# LPC844 register map
Vendor: nxp.com; File version: 1.0
CPU: CM0PLUS r0p0, little endian, no MPU, no FPU, VTOR, 2 interrupt priority bits
Registers are 32-bit, read-write, reset 0x0 unless marked. A register's access mark holds for its fields unless they carry their own. Offsets are from the block's base; [hi:lo] are bit positions; {n}, {i} and the like mark numbered series.

## SWM0 — LPC84x SWM
Base 0x4000C000
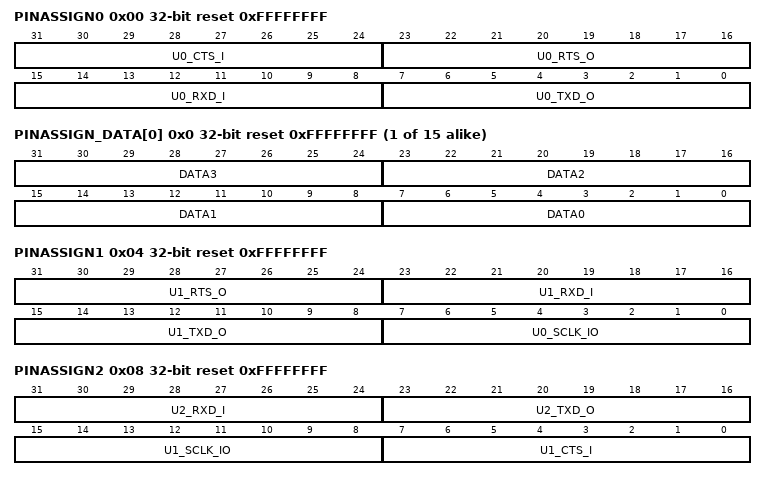
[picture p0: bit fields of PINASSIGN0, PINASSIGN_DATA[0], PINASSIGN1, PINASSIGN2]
0x00 PINASSIGN0 reset 0xFFFFFFFF (PINASSIGN_PINASSIGN_DATA view) — Pin assign register 0. Assign movable functions U0_TXD, U0_RXD, U0_RTS, U0_CTS.
  [31:24] U0_CTS_I — U0_CTS function assignment. The value is the pin number to be assigned to this function. The following pins are available: PIO0_0 (= 0) to PIO0_31 (= 0x1F) and from PIO1_0 (=0x20) to PIO1_21(=0x35).
  [23:16] U0_RTS_O — U0_RTS function assignment. The value is the pin number to be assigned to this function. The following pins are available: PIO0_0 (= 0) to PIO0_31 (= 0x1F) and from PIO1_0 (=0x20) to PIO1_21(=0x35).
  [15:8] U0_RXD_I — U0_RXD function assignment. The value is the pin number to be assigned to this function. The following pins are available: PIO0_0 (= 0) to PIO0_31 (= 0x1F) and from PIO1_0 (=0x20) to PIO1_21(=0x35).
  [7:0] U0_TXD_O — U0_TXD function assignment. The value is the pin number to be assigned to this function. The following pins are available: PIO0_0 (= 0) to PIO0_31 (= 0x1F) and from PIO1_0 (=0x20) to PIO1_21(=0x35) .
{0x0+4i} PINASSIGN_DATA[{i}] (i=0..14) reset 0xFFFFFFFF (PINASSIGN_PINASSIGN_DATA view) — Pin assign register
  [31:24] DATA3 — T0_CAP2 function assignment. The value is the pin number to be assigned to this function. The following pins are available: PIO0_0 (= 0) to PIO0_31 (= 0x1F) and from PIO1_0 (=0x20) to PIO1_21(=0x35).
  [23:16] DATA2 — T0_CAP1 function assignment. The value is the pin number to be assigned to this function. The following pins are available: PIO0_0 (= 0) to PIO0_31 (= 0x1F) and from PIO1_0 (=0x20) to PIO1_21(=0x35).
  [15:8] DATA1 — T0_CAP0 function assignment. The value is the pin number to be assigned to this function. The following pins are available: PIO0_0 (= 0) to PIO0_31 (= 0x1F) and from PIO1_0 (=0x20) to PIO1_21(=0x35).
  [7:0] DATA0 — T0_MAT3 function assignment. The value is the pin number to be assigned to this function. The following pins are available: PIO0_0 (= 0) to PIO0_31 (= 0x1F) and from PIO1_0 (=0x20) to PIO1_21(=0x35).
0x04 PINASSIGN1 reset 0xFFFFFFFF (PINASSIGN_PINASSIGN_DATA view) — Pin assign register 1. Assign movable functions U0_SCLK, U1_TXD, U1_RXD, U1_RTS.
  [31:24] U1_RTS_O — U1_RTS function assignment. The value is the pin number to be assigned to this function. The following pins are available: PIO0_0 (= 0) to PIO0_31 (= 0x1F) and from PIO1_0 (=0x20) to PIO1_21(=0x35).
  [23:16] U1_RXD_I — U1_RXD function assignment. The value is the pin number to be assigned to this function. The following pins are available: PIO0_0 (= 0) to PIO0_31 (= 0x1F) and from PIO1_0 (=0x20) to PIO1_21(=0x35).
  [15:8] U1_TXD_O — U1_TXD function assignment. The value is the pin number to be assigned to this function. The following pins are available: PIO0_0 (= 0) to PIO0_31 (= 0x1F) and from PIO1_0 (=0x20) to PIO1_21(=0x35).
  [7:0] U0_SCLK_IO — U0_SCLK function assignment. The value is the pin number to be assigned to this function. The following pins are available: PIO0_0 (= 0) to PIO0_31 (= 0x1F) and from PIO1_0 (=0x20) to PIO1_21(=0x35).
0x08 PINASSIGN2 reset 0xFFFFFFFF (PINASSIGN_PINASSIGN_DATA view) — Pin assign register 2. Assign movable functions U1_CTS, U1_SCLK, U2_TXD, U2_RXD.
  [31:24] U2_RXD_I — U2_RXD function assignment. The value is the pin number to be assigned to this function. The following pins are available: PIO0_0 (= 0) to PIO0_31 (= 0x1F) and from PIO1_0 (=0x20) to PIO1_21(=0x35).
  [23:16] U2_TXD_O — U2_TXD function assignment. The value is the pin number to be assigned to this function. The following pins are available: PIO0_0 (= 0) to PIO0_31 (= 0x1F) and from PIO1_0 (=0x20) to PIO1_21(=0x35).
  [15:8] U1_SCLK_IO — U1_SCLK function assignment. The value is the pin number to be assigned to this function. The following pins are available: PIO0_0 (= 0) to PIO0_31 (= 0x1F) and from PIO1_0 (=0x20) to PIO1_21(=0x35).
  [7:0] U1_CTS_I — U1_CTS function assignment. The value is the pin number to be assigned to this function. The following pins are available: PIO0_0 (= 0) to PIO0_31 (= 0x1F) and from PIO1_0 (=0x20) to PIO1_21(=0x35).
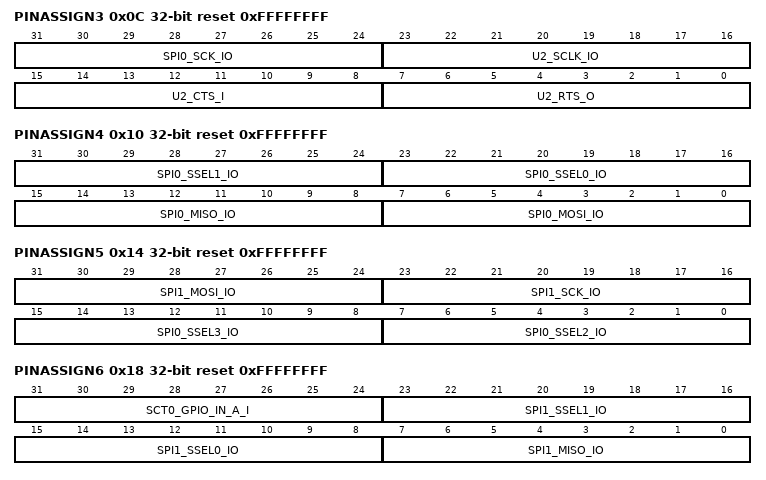
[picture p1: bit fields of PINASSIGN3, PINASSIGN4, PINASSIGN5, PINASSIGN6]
0x0C PINASSIGN3 reset 0xFFFFFFFF (PINASSIGN_PINASSIGN_DATA view) — Pin assign register 3. Assign movable function U2_RTS, U2_CTS, U2_SCLK, SPI0_SCK.
  [31:24] SPI0_SCK_IO — SPI0_SCK function assignment. The value is the pin number to be assigned to this function. The following pins are available: PIO0_0 (= 0) to PIO0_31 (= 0x1F) and from PIO1_0 (=0x20) to PIO1_21(=0x35).
  [23:16] U2_SCLK_IO — U2_SCLK function assignment. The value is the pin number to be assigned to this function. The following pins are available: PIO0_0 (= 0) to PIO0_31 (= 0x1F) and from PIO1_0 (=0x20) to PIO1_21(=0x35).
  [15:8] U2_CTS_I — U2_CTS function assignment. The value is the pin number to be assigned to this function. The following pins are available: PIO0_0 (= 0) to PIO0_31 (= 0x1F) and from PIO1_0 (=0x20) to PIO1_21(=0x35).
  [7:0] U2_RTS_O — U2_RTS function assignment. The value is the pin number to be assigned to this function. The following pins are available: PIO0_0 (= 0) to PIO0_31 (= 0x1F) and from PIO1_0 (=0x20) to PIO1_21(=0x35).
0x10 PINASSIGN4 reset 0xFFFFFFFF (PINASSIGN_PINASSIGN_DATA view) — Pin assign register 4. Assign movable functions SPI0_MOSI, SPI0_MISO, SPI0_SSEL0, SPI0_SSEL1.
  [31:24] SPI0_SSEL1_IO — SPI0_SSEL1 function assignment. The value is the pin number to be assigned to this function. The following pins are available: PIO0_0 (= 0) to PIO0_31 (= 0x1F) and from PIO1_0 (=0x20) to PIO1_21(=0x35).
  [23:16] SPI0_SSEL0_IO — SPI0_SSEL0 function assignment. The value is the pin number to be assigned to this function. The following pins are available: PIO0_0 (= 0) to PIO0_31 (= 0x1F) and from PIO1_0 (=0x20) to PIO1_21(=0x35).
  [15:8] SPI0_MISO_IO — SPI0_MISIO function assignment. The value is the pin number to be assigned to this function. The following pins are available: PIO0_0 (= 0) to PIO0_31 (= 0x1F) and from PIO1_0 (=0x20) to PIO1_21(=0x35).
  [7:0] SPI0_MOSI_IO — SPI0_MOSI function assignment. The value is the pin number to be assigned to this function. The following pins are available: PIO0_0 (= 0) to PIO0_31 (= 0x1F) and from PIO1_0 (=0x20) to PIO1_21(=0x35).
0x14 PINASSIGN5 reset 0xFFFFFFFF (PINASSIGN_PINASSIGN_DATA view) — Pin assign register 5. Assign movable functions SPI0_SSEL2, SPI0_SSEL3, SPI1_SCK, SPI1_MOSI
  [31:24] SPI1_MOSI_IO — SPI1_MOSI function assignment. The value is the pin number to be assigned to this function. The following pins are available: PIO0_0 (= 0) to PIO0_31 (= 0x1F) and from PIO1_0 (=0x20) to PIO1_21(=0x35).
  [23:16] SPI1_SCK_IO — SPI1_SCK function assignment. The value is the pin number to be assigned to this function. The following pins are available: PIO0_0 (= 0) to PIO0_31 (= 0x1F) and from PIO1_0 (=0x20) to PIO1_21(=0x35).
  [15:8] SPI0_SSEL3_IO — SPI0_SSEL3 function assignment. The value is the pin number to be assigned to this function. The following pins are available: PIO0_0 (= 0) to PIO0_31 (= 0x1F) and from PIO1_0 (=0x20) to PIO1_21(=0x35).
  [7:0] SPI0_SSEL2_IO — SPI0_SSEL2 function assignment. The value is the pin number to be assigned to this function. The following pins are available: PIO0_0 (= 0) to PIO0_31 (= 0x1F) and from PIO1_0 (=0x20) to PIO1_21(=0x35).
0x18 PINASSIGN6 reset 0xFFFFFFFF (PINASSIGN_PINASSIGN_DATA view) — Pin assign register 6. Assign movable functions SPI1_MISO, SPI1_SSEL0, SPI1_SSEL1, SCT0_IN0.
  [31:24] SCT0_GPIO_IN_A_I — SCT0_GPIO_IN_A function assignment. The value is the pin number to be assigned to this function. The following pins are available: PIO0_0 (= 0) to PIO0_31 (= 0x1F) and from PIO1_0 (=0x20) to PIO1_21(=0x35).
  [23:16] SPI1_SSEL1_IO — SPI1_SSEL1 function assignment. The value is the pin number to be assigned to this function. The following pins are available: PIO0_0 (= 0) to PIO0_31 (= 0x1F) and from PIO1_0 (=0x20) to PIO1_21(=0x35).
  [15:8] SPI1_SSEL0_IO — SPI1_SSEL0 function assignment. The value is the pin number to be assigned to this function. The following pins are available: PIO0_0 (= 0) to PIO0_31 (= 0x1F) and from PIO1_0 (=0x20) to PIO1_21(=0x35).
  [7:0] SPI1_MISO_IO — SPI1_MISO function assignment. The value is the pin number to be assigned to this function. The following pins are available: PIO0_0 (= 0) to PIO0_31 (= 0x1F) and from PIO1_0 (=0x20) to PIO1_21(=0x35).
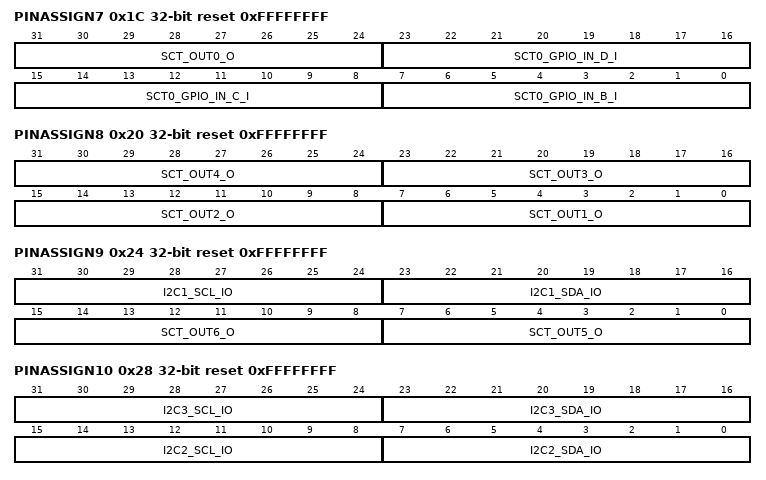
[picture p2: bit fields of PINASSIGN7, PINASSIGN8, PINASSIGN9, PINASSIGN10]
0x1C PINASSIGN7 reset 0xFFFFFFFF (PINASSIGN_PINASSIGN_DATA view) — Pin assign register 7. Assign movable functions SCT_IN1, SCT_IN2, SCT_IN3, SCT_OUT0.
  [31:24] SCT_OUT0_O — SCT_OUT0 function assignment. The value is the pin number to be assigned to this function. The following pins are available: PIO0_0 (= 0) to PIO0_31 (= 0x1F) and from PIO1_0 (=0x20) to PIO1_21(=0x35).
  [23:16] SCT0_GPIO_IN_D_I — SCT0_GPIO_IN_D function assignment. The value is the pin number to be assigned to this function. The following pins are available: PIO0_0 (= 0) to PIO0_31 (= 0x1F) and from PIO1_0 (=0x20) to PIO1_21(=0x35).
  [15:8] SCT0_GPIO_IN_C_I — SCT0_GPIO_IN_C function assignment. The value is the pin number to be assigned to this function. The following pins are available: PIO0_0 (= 0) to PIO0_31 (= 0x1F) and from PIO1_0 (=0x20) to PIO1_21(=0x35).
  [7:0] SCT0_GPIO_IN_B_I — SCT0_GPIO_IN_B function assignment. The value is the pin number to be assigned to this function. The following pins are available: PIO0_0 (= 0) to PIO0_31 (= 0x1F) and from PIO1_0 (=0x20) to PIO1_21(=0x35).
0x20 PINASSIGN8 reset 0xFFFFFFFF (PINASSIGN_PINASSIGN_DATA view) — Pin assign register 8. Assign movable functions SCT_OUT1, SCT_OUT2, SCT_OUT3, SCT_OUT4.
  [8n-1:8n-8] SCT_OUT{n}_O (n=1..4) — SCT_OUT{n} function assignment. The value is the pin number to be assigned to this function. The following pins are available: PIO0_0 (= 0) to PIO0_31 (= 0x1F) and from PIO1_0 (=0x20) to PIO1_21(=0x35).
0x24 PINASSIGN9 reset 0xFFFFFFFF (PINASSIGN_PINASSIGN_DATA view) — Pin assign register 9. Assign movable functions SCT_OUT5, SCT_OUT6, I2C1_SDA, I2C1_SCL.
  [31:24] I2C1_SCL_IO — I2C1_SCL function assignment. The value is the pin number to be assigned to this function. The following pins are available: PIO0_0 (= 0) to PIO0_31 (= 0x1F) and from PIO1_0 (=0x20) to PIO1_21(=0x35).
  [23:16] I2C1_SDA_IO — I2C1_SDA function assignment. The value is the pin number to be assigned to this function. The following pins are available: PIO0_0 (= 0) to PIO0_31 (= 0x1F) and from PIO1_0 (=0x20) to PIO1_21(=0x35).
  [15:8] SCT_OUT6_O — SCT_OUT6 function assignment. The value is the pin number to be assigned to this function. The following pins are available: PIO0_0 (= 0) to PIO0_31 (= 0x1F) and from PIO1_0 (=0x20) to PIO1_21(=0x35).
  [7:0] SCT_OUT5_O — SCT_OUT5 function assignment. The value is the pin number to be assigned to this function. The following pins are available: PIO0_0 (= 0) to PIO0_31 (= 0x1F) and from PIO1_0 (=0x20) to PIO1_21(=0x35).
0x28 PINASSIGN10 reset 0xFFFFFFFF (PINASSIGN_PINASSIGN_DATA view) — Pin assign register 10. Assign movable functions I2C2_SDA, I2C2_SCL, I2C3_SDA, I2C3_SCL, ADC_PINTRIG0.
  [31:24] I2C3_SCL_IO — I2C3_SCL function assignment. The value is the pin number to be assigned to this function. The following pins are available: PIO0_0 (= 0) to PIO0_31 (= 0x1F) and from PIO1_0 (=0x20) to PIO1_21(=0x35).
  [23:16] I2C3_SDA_IO — I2C3_SDA function assignment. The value is the pin number to be assigned to this function. The following pins are available: PIO0_0 (= 0) to PIO0_31 (= 0x1F) and from PIO1_0 (=0x20) to PIO1_21(=0x35).
  [15:8] I2C2_SCL_IO — I2C1_SCL function assignment. The value is the pin number to be assigned to this function. The following pins are available: PIO0_0 (= 0) to PIO0_31 (= 0x1F) and from PIO1_0 (=0x20) to PIO1_21(=0x35).
  [7:0] I2C2_SDA_IO — I2C1_SDA function assignment. The value is the pin number to be assigned to this function. The following pins are available: PIO0_0 (= 0) to PIO0_31 (= 0x1F) and from PIO1_0 (=0x20) to PIO1_21(=0x35).
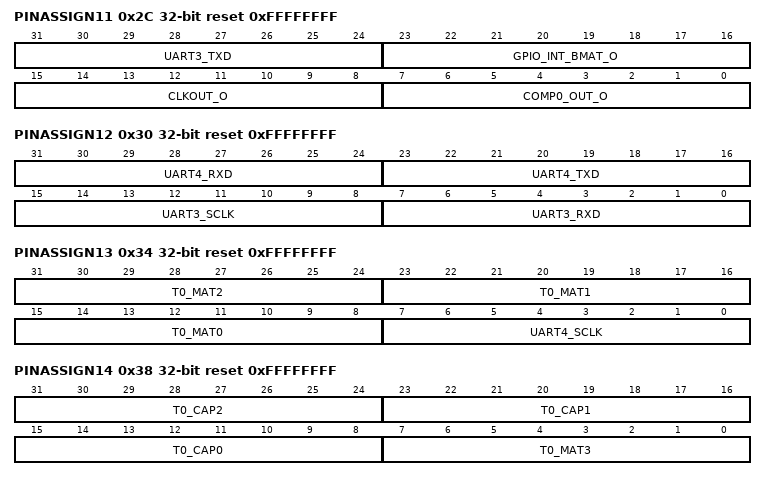
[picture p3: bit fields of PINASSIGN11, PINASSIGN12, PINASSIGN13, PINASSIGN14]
0x2C PINASSIGN11 reset 0xFFFFFFFF (PINASSIGN_PINASSIGN_DATA view) — Pin assign register 11. Assign movable functions COMP0_OUT, CLKOUT, GPIOINT_BMATCH, UART3_TXD
  [31:24] UART3_TXD — UART3_TXD function assignment. The value is the pin number to be assigned to this function. The following pins are available: PIO0_0 (= 0) to PIO0_31 (= 0x1F) and from PIO1_0 (=0x20) to PIO1_21(=0x35).
  [23:16] GPIO_INT_BMAT_O — GPIO_INT_BMAT function assignment. The value is the pin number to be assigned to this function. The following pins are available: PIO0_0 (= 0) to PIO0_31 (= 0x1F) and from PIO1_0 (=0x20) to PIO1_21(=0x35).
  [15:8] CLKOUT_O — CLKOUT function assignment. The value is the pin number to be assigned to this function. The following pins are available: PIO0_0 (= 0) to PIO0_31 (= 0x1F) and from PIO1_0 (=0x20) to PIO1_21(=0x35).
  [7:0] COMP0_OUT_O — COMP0_OUT function assignment. The value is the pin number to be assigned to this function. The following pins are available: PIO0_0 (= 0) to PIO0_31 (= 0x1F) and from PIO1_0 (=0x20) to PIO1_21(=0x35).
0x30 PINASSIGN12 reset 0xFFFFFFFF (PINASSIGN_PINASSIGN_DATA view) — Pin assign register 12. Assign movable functions UART3_RXD, UART3_SCLK, UART4_TXD, UART4_RXD.
  [31:24] UART4_RXD — UART4_TXD function assignment. The value is the pin number to be assigned to this function. The following pins are available: PIO0_0 (= 0) to PIO0_31 (= 0x1F) and from PIO1_0 (=0x20) to PIO1_21(=0x35).
  [23:16] UART4_TXD — UART4_TXD function assignment. The value is the pin number to be assigned to this function. The following pins are available: PIO0_0 (= 0) to PIO0_31 (= 0x1F) and from PIO1_0 (=0x20) to PIO1_21(=0x35).
  [15:8] UART3_SCLK — UART3_SCLK function assignment. The value is the pin number to be assigned to this function. The following pins are available: PIO0_0 (= 0) to PIO0_31 (= 0x1F) and from PIO1_0 (=0x20) to PIO1_21(=0x35).
  [7:0] UART3_RXD — UART3_RXD function assignment. The value is the pin number to be assigned to this function. The following pins are available: PIO0_0 (= 0) to PIO0_31 (= 0x1F) and from PIO1_0 (=0x20) to PIO1_21(=0x35).
0x34 PINASSIGN13 reset 0xFFFFFFFF (PINASSIGN_PINASSIGN_DATA view) — Pin assign register 13. Assign movable functions UART4_SCLK, T0_MAT0, T0_MAT1, T0_MAT2.
  [31:24] T0_MAT2 — T0_MAT2 function assignment. The value is the pin number to be assigned to this function. The following pins are available: PIO0_0 (= 0) to PIO0_31 (= 0x1F) and from PIO1_0 (=0x20) to PIO1_21(=0x35).
  [23:16] T0_MAT1 — T0_MAT1 function assignment. The value is the pin number to be assigned to this function. The following pins are available: PIO0_0 (= 0) to PIO0_31 (= 0x1F) and from PIO1_0 (=0x20) to PIO1_21(=0x35).
  [15:8] T0_MAT0 — T0_MAT0 function assignment. The value is the pin number to be assigned to this function. The following pins are available: PIO0_0 (= 0) to PIO0_31 (= 0x1F) and from PIO1_0 (=0x20) to PIO1_21(=0x35).
  [7:0] UART4_SCLK — UART4_SCLK function assignment. The value is the pin number to be assigned to this function. The following pins are available: PIO0_0 (= 0) to PIO0_31 (= 0x1F) and from PIO1_0 (=0x20) to PIO1_21(=0x35).
0x38 PINASSIGN14 reset 0xFFFFFFFF (PINASSIGN_PINASSIGN_DATA view) — Pin assign register 14. Assign movable functions T0_MAT3, T0_CAP0, T0_CAP1, T0_CAP2.
  [31:24] T0_CAP2 — T0_CAP2 function assignment. The value is the pin number to be assigned to this function. The following pins are available: PIO0_0 (= 0) to PIO0_31 (= 0x1F) and from PIO1_0 (=0x20) to PIO1_21(=0x35).
  [23:16] T0_CAP1 — T0_CAP1 function assignment. The value is the pin number to be assigned to this function. The following pins are available: PIO0_0 (= 0) to PIO0_31 (= 0x1F) and from PIO1_0 (=0x20) to PIO1_21(=0x35).
  [15:8] T0_CAP0 — T0_CAP0 function assignment. The value is the pin number to be assigned to this function. The following pins are available: PIO0_0 (= 0) to PIO0_31 (= 0x1F) and from PIO1_0 (=0x20) to PIO1_21(=0x35).
  [7:0] T0_MAT3 — T0_MAT3 function assignment. The value is the pin number to be assigned to this function. The following pins are available: PIO0_0 (= 0) to PIO0_31 (= 0x1F) and from PIO1_0 (=0x20) to PIO1_21(=0x35).
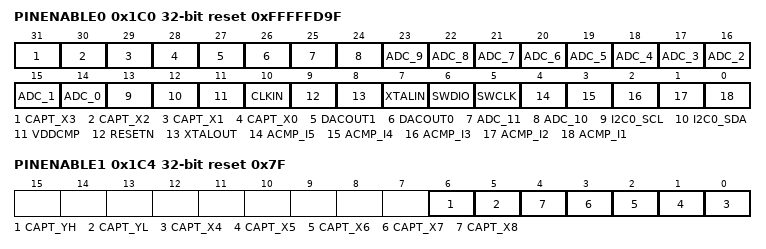
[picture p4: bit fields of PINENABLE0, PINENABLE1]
0x1C0 PINENABLE0 reset 0xFFFFFD9F — Pin enable register 0. Enables fixed-pin functions ACMP_I0, ACMP_I1, SWCLK, SWDIO, XTALIN, XTALOUT, RESET, CLKIN, VDDCMP and so on.
  [31] CAPT_X3 — CAPT_X3 function select.
    0=ENABLED (CAPT_X3 enabled on pin PIO1_2.); 1=DISABLED (CAPT_X3 disabled.)
  [30] CAPT_X2 — CAPT_X2 function select.
    0=ENABLED (CAPT_X2 enabled on pin PIO1_1.); 1=DISABLED (CAPT_X2 disabled.)
  [29] CAPT_X1 — CAPT_X1 function select.
    0=ENABLED (CAPT_X1 enabled on pin PIO1_0.); 1=DISABLED (CAPT_X1 disabled.)
  [28] CAPT_X0 — CAPT_X0 function select.
    0=ENABLED (CAPT_X0 enabled on pin PIO0_31.); 1=DISABLED (CAPT_X0 disabled.)
  [27] DACOUT1 — DACOUT1 function select.
    0=ENABLED (DACOUT1 enabled on pin PIO0_29.); 1=DISABLED (DACOUT1 disabled.)
  [26] DACOUT0 — DACOUT0 function select.
    0=ENABLED (DACOUT0 enabled on pin PIO0_17.); 1=DISABLED (DACOUT0 disabled.)
  [25] ADC_11 — ADC_11 function select.
    0=ENABLED (ADC_11 enabled on pin PIO0_4.); 1=DISABLED (ADC_11 disabled.)
  [24] ADC_10 — ADC_10 function select.
    0=ENABLED (ADC_10 enabled on pin PIO0_13.); 1=DISABLED (ADC_10 disabled.)
  [23] ADC_9 — ADC_9 function select.
    0=ENABLED (ADC_9 enabled on pin PIO0_17.); 1=DISABLED (ADC_9 disabled.)
  [22] ADC_8 — ADC_8 function select.
    0=ENABLED (ADC_8 enabled on pin PIO0_18.); 1=DISABLED (ADC_8 disabled.)
  [21] ADC_7 — ADC_7 function select.
    0=ENABLED (ADC_7 enabled on pin PIO0_19.); 1=DISABLED (ADC_7 disabled.)
  [20] ADC_6 — ADC_6 function select.
    0=ENABLED (ADC_6 enabled on pin PIO0_20.); 1=DISABLED (ADC_6 disabled.)
  [19] ADC_5 — ADC_5 function select.
    0=ENABLED (ADC_5 enabled on pin PIO0_21.); 1=DISABLED (ADC_5 disabled.)
  [18] ADC_4 — ADC_4 function select.
    0=ENABLED (ADC_4 enabled on pin PIO0_22.); 1=DISABLED (ADC_4 disabled.)
  [17] ADC_3 — ADC_3 function select.
    0=ENABLED (ADC_3 enabled on pin PIO0_23.); 1=DISABLED (ADC_3 disabled.)
  [16] ADC_2 — ADC_2 function select.
    0=ENABLED (ADC_2 enabled on pin PIO0_14.); 1=DISABLED (ADC_2 disabled.)
  [15] ADC_1 — ADC_1 function select.
    0=ENABLED (ADC_1 enabled on pin PIO0_6.); 1=DISABLED (ADC_1 disabled.)
  [14] ADC_0 — ADC_0 function select.
    0=ENABLED (ADC_0 enabled on pin PIO0_7.); 1=DISABLED (ADC_0 disabled.)
  [13] I2C0_SCL — I2C0_SCL function select.
    0=ENABLED (I2C0_SCL enabled on pin PIO0_10.); 1=DISABLED (I2C0_SCL disabled.)
  [12] I2C0_SDA — I2C0_SDA function select.
    0=ENABLED (I2C0_SDA enabled on pin PIO0_11.); 1=DISABLED (I2C0_SDA disabled.)
  [11] VDDCMP — VDDCMP function select.
    0=ENABLED (VDDCMP enabled on pin PIO0_6.); 1=DISABLED (VDDCMP disabled.)
  [10] CLKIN — CLKIN function select.
    0=ENABLED (CLKIN enabled on pin PIO0_1.); 1=DISABLED (CLKIN disabled.)
  [9] RESETN — RESETN function select.
    0=ENABLED (RESETN enabled on pin PIO0_5.); 1=DISABLED (RESETN disabled.)
  [8] XTALOUT — XTALOUT function select.
    0=ENABLED (XTALOUT enabled on pin PIO0_9.); 1=DISABLED (XTALOUT disabled.)
  [7] XTALIN — XTALIN function select.
    0=ENABLED (XTALIN enabled on pin PIO0_8.); 1=DISABLED (XTALIN disabled.)
  [6] SWDIO — SWDIO function select.
    0=ENABLED (SWDIO enabled on pin PIO0_2.); 1=DISABLED (SWDIO disabled.)
  [5] SWCLK — SWCLK function select.
    0=ENABLED (SWCLK enabled on pin PIO0_3.); 1=DISABLED (SWCLK disabled.)
  [4] ACMP_I5 — ACMP_I5 function select.
    0=ENABLED (ACMP_I5 enabled on pin PIO0_30.); 1=DISABLED (ACMP_I5 disabled.)
  [3] ACMP_I4 — ACMP_I4 function select.
    0=ENABLED (ACMP_I4 enabled on pin PIO0_23.); 1=DISABLED (ACMP_I4 disabled.)
  [2] ACMP_I3 — ACMP_I3 function select.
    0=ENABLED (ACMP_I3 enabled on pin PIO0_14.); 1=DISABLED (ACMP_I3 disabled.)
  [1] ACMP_I2 — ACMP_I2 function select.
    0=ACMP_I2 enabled on pin PIO0_1; 1=ACMP_I2 disabled
  [0] ACMP_I1 — ACMP_I1 function select.
    0=ENABLED (ACMP_I1 enabled on pin PIO0_00.); 1=DISABLED (ACMP_I1 disabled.)
0x1C4 PINENABLE1 reset 0x7F — Pin enable register 1. Enables fixed-pin functions CAPT_X4, CAPT_X5, CAPT_X6, CAPT_X7, CAPT_X8, CAPT_X4, CAPT_YL and CAPT_YH.
  [6] CAPT_YH — CAPT_YH function select.
    0=ENABLED (CAPT_YH enabled on pin PIO1_9.); 1=DISABLED (CAPT_YH disabled.)
  [5] CAPT_YL — CAPT_YL function select.
    0=ENABLED (CAPT_YL enabled on pin PIO1_8.); 1=DISABLED (CAPT_YL disabled.)
  [n-4] CAPT_X{n} (n=4..8) — CAPT_X{n} function select.
    0=ENABLED (CAPT_X{n} enabled on pin PIO1_{n-1}.); 1=DISABLED (CAPT_X{n} disabled.)
